# M344 register map
File version: 2.0.2.6
Registers are 32-bit, read-write, reset 0x0 unless marked. A register's access mark holds for its fields unless they carry their own. Offsets are from the block's base; [hi:lo] are bit positions; {n}, {i} and the like mark numbered series.

## PF — Port F
Base 0x400C0500
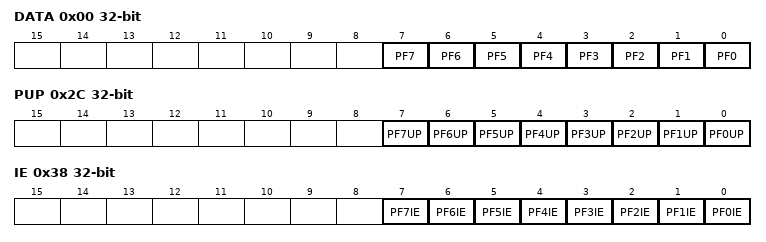
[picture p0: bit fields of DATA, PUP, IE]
0x00 DATA — Port F Data Register
  [n] PF{n} (n=0..7)
0x2C PUP — Port F Pull-up Control Register
  [n] PF{n}UP (n=0..7)
0x38 IE — Port F Input Control Register
  [n] PF{n}IE (n=0..7)

## PG — Port G
Base 0x400C0600
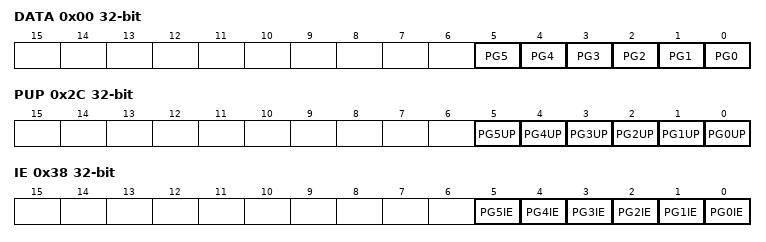
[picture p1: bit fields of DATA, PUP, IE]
0x00 DATA — Port G Data Register
  [n] PG{n} (n=0..5)
0x2C PUP — Port G Pull-up Control Register
  [n] PG{n}UP (n=0..5)
0x38 IE — Port G Input Control Register
  [n] PG{n}IE (n=0..5)

## PH — Port H
Base 0x400C0700
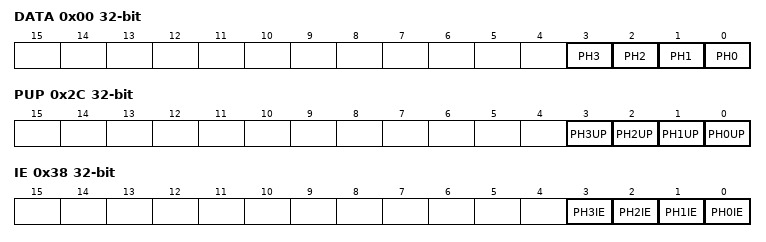
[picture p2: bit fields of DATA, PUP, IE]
0x00 DATA — Port H Data Register
  [n] PH{n} (n=0..3)
0x2C PUP — Port H Pull-up Control Register
  [n] PH{n}UP (n=0..3)
0x38 IE — Port H Input Control Register
  [n] PH{n}IE (n=0..3)

## PJ — Port J
Base 0x400C0800
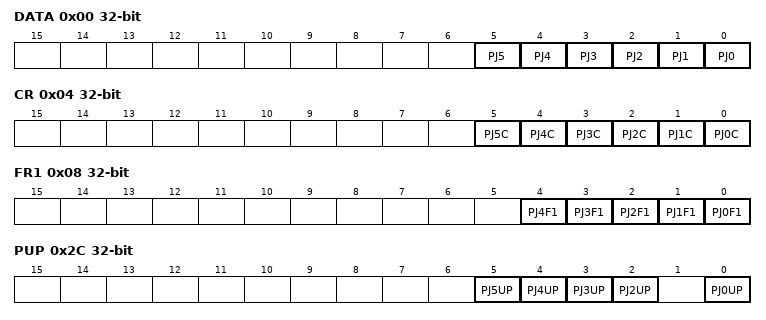
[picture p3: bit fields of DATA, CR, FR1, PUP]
0x00 DATA — Port J Data Register
  [n] PJ{n} (n=0..5)
0x04 CR — Port J Output Control Register
  [n] PJ{n}C (n=0..5)
0x08 FR1 — Port J Function Register 1
  [n] PJ{n}F1 (n=0..4)
0x2C PUP — Port J Pull-up Control Register
  [n] PJ{n}UP (n=2..5), [0] PJ0UP
0x30 PDN — Port J Pull-down Control Register
  [1] PJ1DN
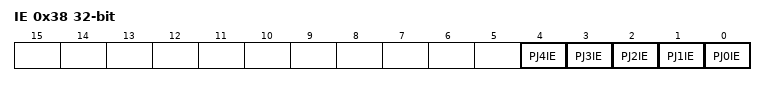
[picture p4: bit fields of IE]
0x38 IE — Port J Input Control Register
  [n] PJ{n}IE (n=0..4)

## PK — Port K
Base 0x400C0900
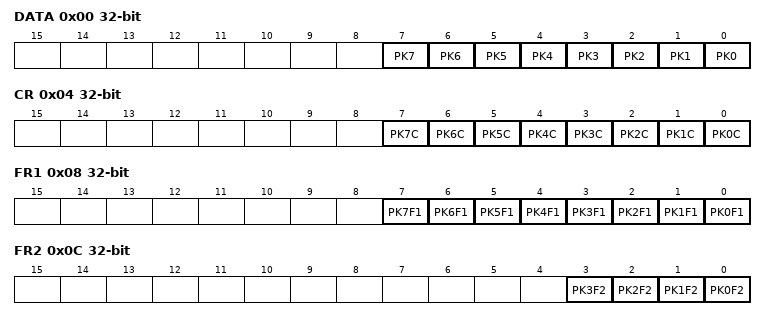
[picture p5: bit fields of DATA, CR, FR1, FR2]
0x00 DATA — Port K Data Register
  [n] PK{n} (n=0..7)
0x04 CR — Port K Output Control Register
  [n] PK{n}C (n=0..7)
0x08 FR1 — Port K Function Register 1
  [n] PK{n}F1 (n=0..7)
0x0C FR2 — Port K Function Register 2
  [n] PK{n}F2 (n=0..3)
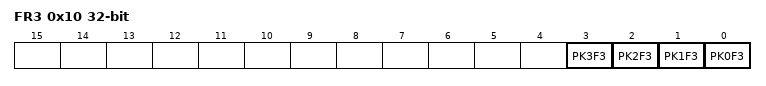
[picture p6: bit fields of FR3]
0x10 FR3 — Port K Function Register 3
  [n] PK{n}F3 (n=0..3)

## PL — Port L
Base 0x400C0A00
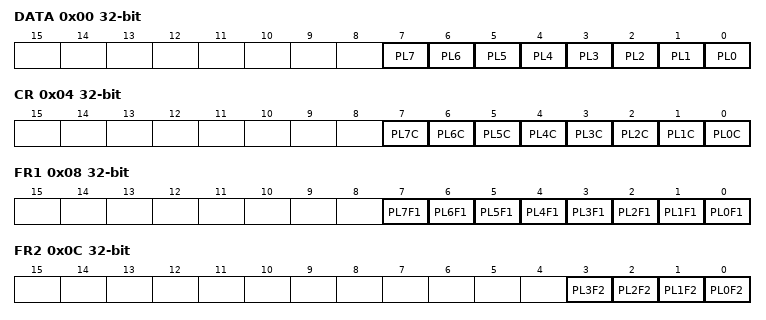
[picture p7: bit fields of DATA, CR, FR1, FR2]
0x00 DATA — Port L Data Register
  [n] PL{n} (n=0..7)
0x04 CR — Port L Output Control Register
  [n] PL{n}C (n=0..7)
0x08 FR1 — Port L Function Register 1
  [n] PL{n}F1 (n=0..7)
0x0C FR2 — Port L Function Register 2
  [n] PL{n}F2 (n=0..3)
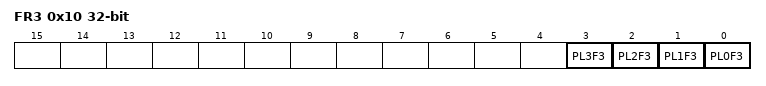
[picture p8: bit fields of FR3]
0x10 FR3 — Port L Function Register 3
  [n] PL{n}F3 (n=0..3)

## PM — Port M
Base 0x400C0B00
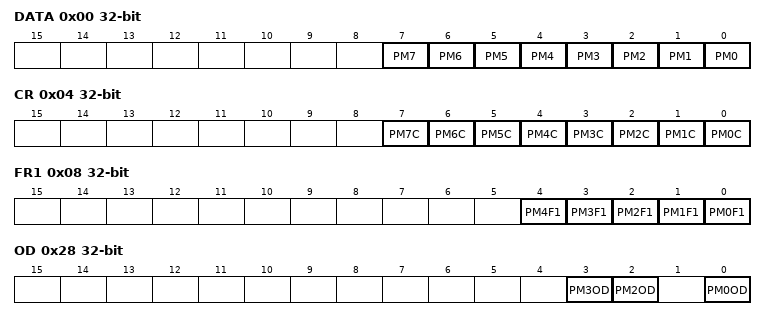
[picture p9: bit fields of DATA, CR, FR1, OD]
0x00 DATA — Port M Data Register
  [n] PM{n} (n=0..7)
0x04 CR — Port M Output Control Register
  [n] PM{n}C (n=0..7)
0x08 FR1 — Port M Function Register 1
  [n] PM{n}F1 (n=0..4)
0x28 OD — Port M Open Drain Register
  [3] PM3OD, [2] PM2OD, [0] PM0OD
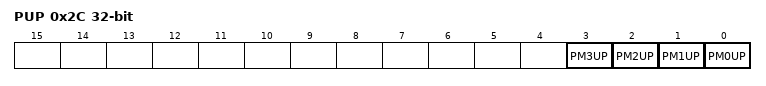
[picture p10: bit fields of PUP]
0x2C PUP — Port M Pull-up Control Register
  [n] PM{n}UP (n=0..3)

## PN — Port N
Base 0x400C0C00
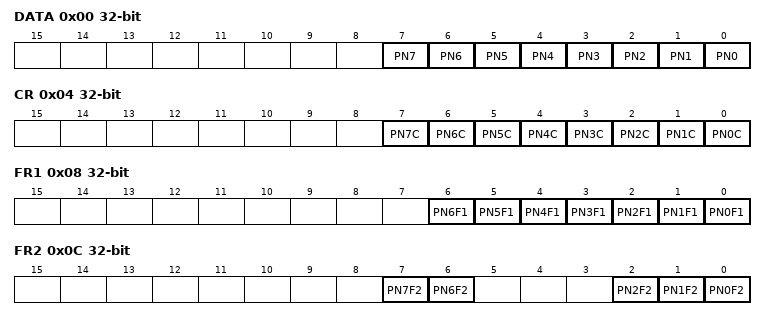
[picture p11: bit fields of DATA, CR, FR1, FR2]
0x00 DATA — Port N Data Register
  [n] PN{n} (n=0..7)
0x04 CR — Port N Output Control Register
  [n] PN{n}C (n=0..7)
0x08 FR1 — Port N Function Register 1
  [n] PN{n}F1 (n=0..6)
0x0C FR2 — Port N Function Register 2
  [7] PN7F2, [6] PN6F2, [2] PN2F2, [1] PN1F2, [0] PN0F2
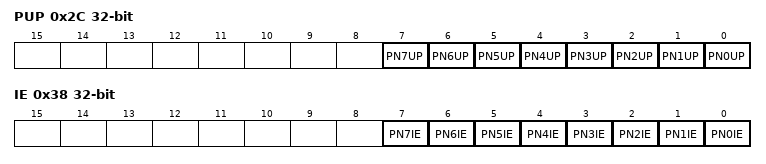
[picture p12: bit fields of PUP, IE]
0x2C PUP — Port N Pull-up Control Register
  [n] PN{n}UP (n=0..7)
0x38 IE — Port N Input Control Register
  [n] PN{n}IE (n=0..7)

## TBC — 16-bit Timer_Event Counter (TB)
Base 0x401C4C00
Same registers: TBD 0x401C4D00, TBE 0x402C4E00, TBF 0x402C4F00, TB{n} {0x403C4000+0x100*n} (n=0..9), TBA 0x403C4A00, TBB 0x403C4B00
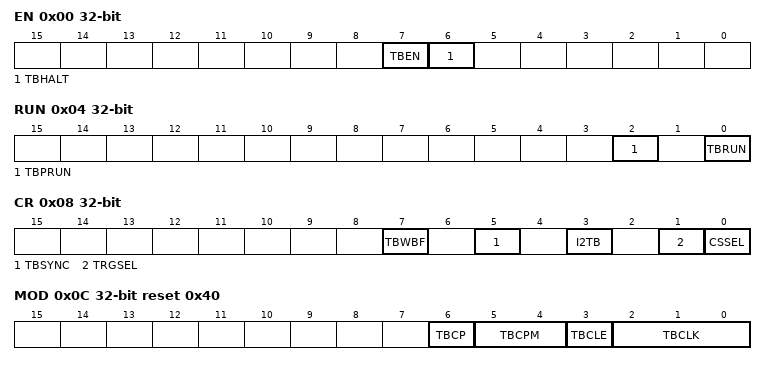
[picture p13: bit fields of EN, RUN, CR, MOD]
0x00 EN — TB Enable Register
  [7] TBEN, [6] TBHALT
0x04 RUN — TB RUN Register
  [2] TBPRUN, [0] TBRUN
0x08 CR — TB Control Register
  [7] TBWBF, [5] TBSYNC, [3] I2TB, [1] TRGSEL, [0] CSSEL
0x0C MOD reset 0x40 — TB Mode Register
  [6] TBCP wo, [5:4] TBCPM, [3] TBCLE, [2:0] TBCLK
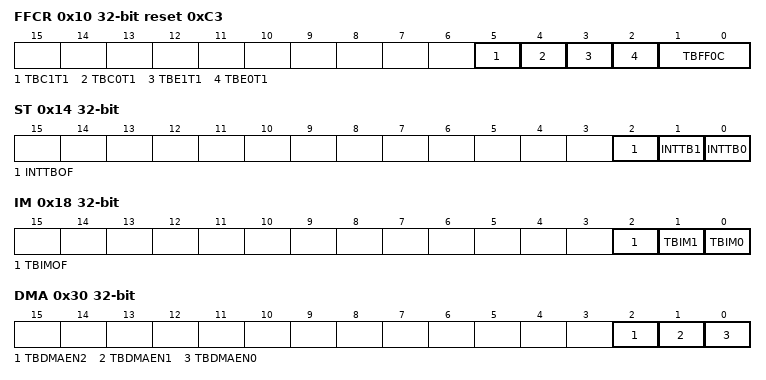
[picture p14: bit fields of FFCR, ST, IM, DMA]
0x10 FFCR reset 0xC3 — TB Flip-Flop Control Register
  [5] TBC1T1, [4] TBC0T1, [3] TBE1T1, [2] TBE0T1, [1:0] TBFF0C
0x14 ST ro — TB Status Register
  [2] INTTBOF, [1] INTTB1, [0] INTTB0
0x18 IM — TB Interrupt Mask Register
  [2] TBIMOF, [1] TBIM1, [0] TBIM0
0x1C UC ro — TB Read Capture Register
  [15:0] TBUC
0x20 RG0 — TB RG0 Timer Register
  [15:0] TBRG0
0x24 RG1 — TB RG1 Timer Register
  [15:0] TBRG1
0x28 CP0 ro (reset mask 0xFFFF0000) — TB CP0 Capture Register
  [15:0] TBCP0
0x2C CP1 ro (reset mask 0xFFFF0000) — TB CP1 Capture Register
  [15:0] TBCP1
0x30 DMA — TB DMA Enable Register
  [2] TBDMAEN2, [1] TBDMAEN1, [0] TBDMAEN0
